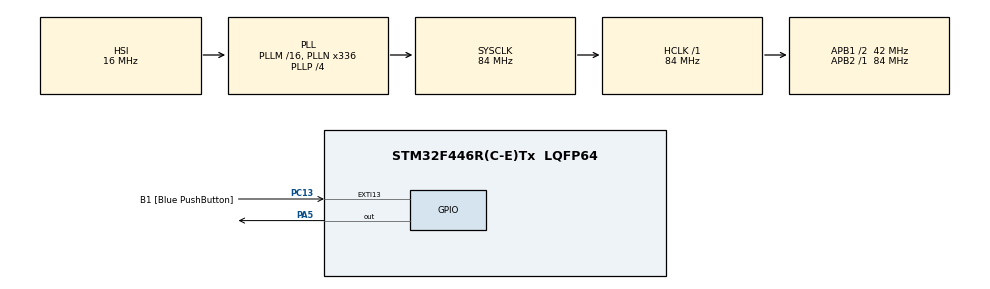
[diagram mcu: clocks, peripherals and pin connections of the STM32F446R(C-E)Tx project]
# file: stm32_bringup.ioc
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Mcu.Family=STM32F4
Mcu.Name=STM32F446R(C-E)Tx
Mcu.Package=LQFP64
NUCLEO-F446RE.LD1=true
NVIC.PriorityGroup=NVIC_PRIORITYGROUP_0
PA13.GPIO_Label=TMS
PA13.Signal=SYS_JTMS-SWDIO
PA14.GPIO_Label=TCK
PA14.Signal=SYS_JTCK-SWCLK
PA2.GPIO_Label=USART_TX
PA2.Signal=USART2_TX
PA3.GPIO_Label=USART_RX
PA3.Signal=USART2_RX
PA5.Signal=GPIO_Output
PB3.GPIO_Label=SWO
PB3.Signal=SYS_JTDO-SWO
PC13.GPIO_Label=B1 [Blue PushButton]
PC13.GPIO_ModeDefaultEXTI=GPIO_MODE_IT_FALLING
PC13.Signal=GPXTI13
PC14-OSC32_IN.Signal=RCC_OSC32_IN
PC15-OSC32_OUT.Signal=RCC_OSC32_OUT
PH0-OSC_IN.Signal=RCC_OSC_IN
PH1-OSC_OUT.Signal=RCC_OSC_OUT
ProjectManager.HeapSize=0x200
ProjectManager.StackSize=0x400
ProjectManager.TargetToolchain=CMake
RCC.AHBFreq_Value=84000000
RCC.APB1CLKDivider=RCC_HCLK_DIV2
RCC.APB1Freq_Value=42000000
RCC.APB1TimFreq_Value=84000000
RCC.APB2Freq_Value=84000000
RCC.APB2TimFreq_Value=84000000
RCC.CortexFreq_Value=84000000
RCC.FLatency-AdvancedSettings=FLASH_LATENCY_2
RCC.HCLKFreq_Value=84000000
RCC.HSE_VALUE=8000000
RCC.HSI_VALUE=16000000
RCC.LSE_VALUE=32768
RCC.PLLN=336
RCC.PLLP=RCC_PLLP_DIV4
RCC.SYSCLKFreq_VALUE=84000000
RCC.SYSCLKSource=RCC_SYSCLKSOURCE_PLLCLK
RCC.USBFreq_Value=168000000
RCC.VCOOutputFreq_Value=336000000
VP_NUCLEO-F446RE_VS_BSP_COMMON.Mode=COMMON
board=NUCLEO-F446RE

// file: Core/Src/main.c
/* USER CODE BEGIN Header */
/**
  ******************************************************************************
  * @file           : main.c
  * @brief          : Main program body
  ******************************************************************************
  * @attention
  *
  * Copyright (c) 2026 STMicroelectronics.
  * All rights reserved.
  *
  * This software is licensed under terms that can be found in the LICENSE file
  * in the root directory of this software component.
  * If no LICENSE file comes with this software, it is provided AS-IS.
  *
  ******************************************************************************
  */
/* USER CODE END Header */
#include "main.h"
#include "stm32_hal_legacy.h"
#include "stm32f446xx.h"
#include "stm32f4xx_hal.h"
#include "stm32f4xx_hal_gpio.h"
#include "uart.h"
#include <string.h>
#include "can.h"
#include "spi.h"
#include "bme280.h"

#define NODE_A_TRANSMITTER  1u
#define NODE_B_RECEIVER     2u

#define NODE_ROLE NODE_A_TRANSMITTER

void SystemClock_Config(void);
static void MX_GPIO_Init(void);

static void handle_command(const char *command)
{
    if (strcmp(command, "led on") == 0)
    {
        /* YOUR CODE: set PA5 using BSRR, then send a confirmation. */
        GPIOA->BSRR = (1u << 5);
        uart2_write_string("LED ON!\r\n");
    }
    else if (strcmp(command, "led off") == 0)
    {
        /* YOUR CODE: reset PA5 using BSRR, then send a confirmation. */
        GPIOA->BSRR = (1u << 21);
        uart2_write_string("LED OFF!\r\n");
    }
    else if (strcmp(command, "help") == 0)
    {
        /* YOUR CODE: print the available commands. */
        uart2_write_string("led on, led off, help\r\n");
    }
    else
    {
        uart2_write_string("Unknown command\r\n");
    }
}

static bool can1_loopback_test(void)
{
  CanFrame expected;

  expected.id = 0x523u;
  expected.length = 8u;

  expected.data[0] = 0x11u;
  expected.data[1] = 0x22u;
  expected.data[2] = 0x33u;
  expected.data[3] = 0x44u;
  expected.data[4] = 0x55u;
  expected.data[5] = 0x66u;
  expected.data[6] = 0x77u;
  expected.data[7] = 0x88u;
  if(!can1_try_send(&expected))
  {
    return false;
  }

  CanFrame received;

  uint32_t start = HAL_GetTick();

  while((HAL_GetTick() - start) < 100)
  {
   if(can1_try_receive(&received)){
      if((received.id != expected.id) || (received.length == expected.length))
      {
        return false;
      }
      for(int i = 0; i < expected.length; i++)
        {
          if(received.data[i] != expected.data[i])
          {
            return false;
          }
        }
        return true;
   }
  }
  return false;
}

static void uart2_write_hex32(uint32_t value)
{
    static const char digits[] = "0123456789ABCDEF";

    for (int shift = 28; shift >= 0; shift -= 4)
    {
        uart2_write_char(digits[(value >> shift) & 0xFu]);
    }
}

int main(void)
{

  /* MCU Configuration--------------------------------------------------------*/

  /* Reset of all peripherals, Initializes the Flash interface and the Systick. */
  HAL_Init();

  /* Configure the system clock */
  SystemClock_Config();

  /* Initialize all configured peripherals */
  MX_GPIO_Init();
  uart2_init();
  /* USER CODE BEGIN 2 */

uart2_write_string("Boot\r\n");

spi2_init();
uart2_write_string("SPI init\r\n");

bme280_init();
uart2_write_string("BME280 init\r\n");

uint32_t raw_pressure;
uint32_t raw_temperature;
uint16_t raw_humidity;

if (bme280_read_raw(&raw_pressure, &raw_temperature, &raw_humidity))
{
    uart2_write_string("BME raw read PASS\r\n");
}
else
{
    uart2_write_string("BME raw read FAIL\r\n");
}

uart2_write_string("P=0x");
uart2_write_hex32(raw_pressure);

uart2_write_string(" T=0x");
uart2_write_hex32(raw_temperature);

uart2_write_string(" H=0x");
uart2_write_hex32(raw_humidity);

uart2_write_string("\r\n");

  __HAL_RCC_GPIOB_CLK_ENABLE();

GPIO_InitTypeDef can_pins = {0};
can_pins.Pin = GPIO_PIN_8 | GPIO_PIN_9;
can_pins.Mode = GPIO_MODE_AF_PP;
can_pins.Pull = GPIO_PULLUP;
can_pins.Speed = GPIO_SPEED_FREQ_HIGH;
can_pins.Alternate = GPIO_AF9_CAN1;

HAL_GPIO_Init(GPIOB, &can_pins);

  /* USER CODE END 2 */

  /* Initialize leds */
  GPIO_InitTypeDef led_config;
  led_config.Pin = GPIO_PIN_5;
  led_config.Mode = GPIO_MODE_OUTPUT_PP;
  led_config.Pull= GPIO_NOPULL;
  led_config.Speed= GPIO_SPEED_FAST;

  HAL_GPIO_Init(GPIOA, &led_config);
  HAL_GPIO_WritePin(GPIOA, GPIO_PIN_5, GPIO_PIN_RESET);

if (!can1_enter_init())
{
    uart2_write_string("CAN: init timeout\r\n");
    Error_Handler();
}

can1_configure_500k_normal();
can1_configure_filter();

if (!can1_start())
{
    uart2_write_string("CAN: start timeout\r\n");
    Error_Handler();
}

uart2_write_string("CAN: normal mode ready\r\n");

  uint32_t last_toggle = HAL_GetTick();

  char command[32];
  uint32_t command_length = 0;
  bool discard_line = false;

  /* Infinite loop */
  /* USER CODE BEGIN WHILE */
 while (1)
{
   #if NODE_ROLE == NODE_A_TRANSMITTER

    static uint32_t last_can_tx = 0u;
    static uint16_t sequence = 0u;

    if ((HAL_GetTick() - last_can_tx) >= 100u)
    {
        CanFrame frame;

        frame.id = 0x120u;
        frame.length = 4u;

        frame.data[0] = (uint8_t)(sequence & 0xFFu);
        frame.data[1] = (uint8_t)(sequence >> 8u);
        frame.data[2] = 0xA5u;
        frame.data[3] = 0x5Au;

        if (can1_try_send(&frame))
        {
            sequence++;
        }

        last_can_tx = HAL_GetTick();
    }

#elif NODE_ROLE == NODE_B_RECEIVER

    CanFrame received;

    if (can1_try_receive(&received))
    {
        if ((received.id == 0x120u) && (received.length == 4u))
        {
            uart2_write_string("CAN RX\r\n");
        }
        else
        {
            uart2_write_string("Unexpected CAN frame\r\n");
        }
    }

#endif
}
  /* USER CODE END 3 */
}

void SystemClock_Config(void)
{
  RCC_OscInitTypeDef RCC_OscInitStruct = {0};
  RCC_ClkInitTypeDef RCC_ClkInitStruct = {0};

  /** Configure the main internal regulator output voltage
  */
  __HAL_RCC_PWR_CLK_ENABLE();
  __HAL_PWR_VOLTAGESCALING_CONFIG(PWR_REGULATOR_VOLTAGE_SCALE3);

  /** Initializes the RCC Oscillators according to the specified parameters
  * in the RCC_OscInitTypeDef structure.
  */
  RCC_OscInitStruct.OscillatorType = RCC_OSCILLATORTYPE_HSI;
  RCC_OscInitStruct.HSIState = RCC_HSI_ON;
  RCC_OscInitStruct.HSICalibrationValue = RCC_HSICALIBRATION_DEFAULT;
  RCC_OscInitStruct.PLL.PLLState = RCC_PLL_ON;
  RCC_OscInitStruct.PLL.PLLSource = RCC_PLLSOURCE_HSI;
  RCC_OscInitStruct.PLL.PLLM = 16;
  RCC_OscInitStruct.PLL.PLLN = 336;
  RCC_OscInitStruct.PLL.PLLP = RCC_PLLP_DIV4;
  RCC_OscInitStruct.PLL.PLLQ = 2;
  RCC_OscInitStruct.PLL.PLLR = 2;
  if (HAL_RCC_OscConfig(&RCC_OscInitStruct) != HAL_OK)
  {
    Error_Handler();
  }

  /** Initializes the CPU, AHB and APB buses clocks
  */
  RCC_ClkInitStruct.ClockType = RCC_CLOCKTYPE_HCLK|RCC_CLOCKTYPE_SYSCLK
                              |RCC_CLOCKTYPE_PCLK1|RCC_CLOCKTYPE_PCLK2;
  RCC_ClkInitStruct.SYSCLKSource = RCC_SYSCLKSOURCE_PLLCLK;
  RCC_ClkInitStruct.AHBCLKDivider = RCC_SYSCLK_DIV1;
  RCC_ClkInitStruct.APB1CLKDivider = RCC_HCLK_DIV2;
  RCC_ClkInitStruct.APB2CLKDivider = RCC_HCLK_DIV1;

  if (HAL_RCC_ClockConfig(&RCC_ClkInitStruct, FLASH_LATENCY_2) != HAL_OK)
  {
    Error_Handler();
  }
}

static void MX_GPIO_Init(void)
{
  GPIO_InitTypeDef GPIO_InitStruct = {0};

  /* GPIO Ports Clock Enable */
  __HAL_RCC_GPIOC_CLK_ENABLE();
  __HAL_RCC_GPIOH_CLK_ENABLE();
  __HAL_RCC_GPIOA_CLK_ENABLE();
  __HAL_RCC_GPIOB_CLK_ENABLE();

  /*Configure GPIO pin : B1_Pin */
  GPIO_InitStruct.Pin = B1_Pin;
  GPIO_InitStruct.Mode = GPIO_MODE_IT_FALLING;
  GPIO_InitStruct.Pull = GPIO_NOPULL;
  HAL_GPIO_Init(B1_GPIO_Port, &GPIO_InitStruct);

  /*Configure GPIO pins : USART_TX_Pin USART_RX_Pin */
  GPIO_InitStruct.Pin = USART_TX_Pin|USART_RX_Pin;
  GPIO_InitStruct.Mode = GPIO_MODE_AF_PP;
  GPIO_InitStruct.Pull = GPIO_NOPULL;
  GPIO_InitStruct.Speed = GPIO_SPEED_FREQ_VERY_HIGH;
  GPIO_InitStruct.Alternate = GPIO_AF7_USART2;
  HAL_GPIO_Init(GPIOA, &GPIO_InitStruct);

}

void Error_Handler(void)
{
  __disable_irq();
  while (1)
  {
  }
}
